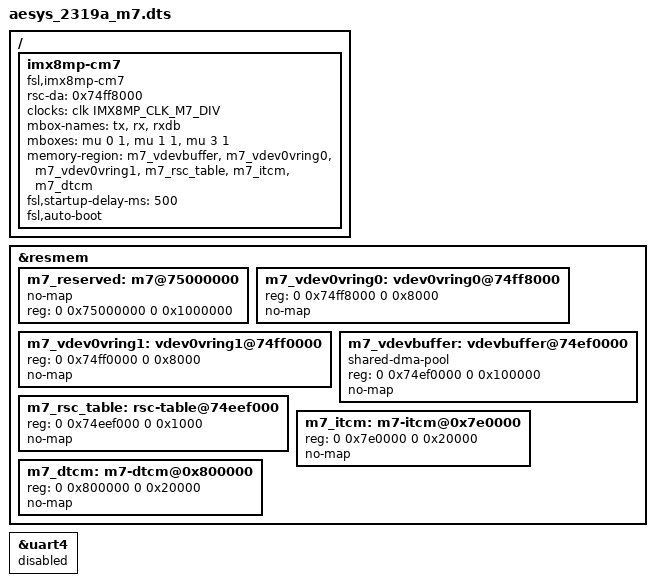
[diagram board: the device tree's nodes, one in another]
// SPDX-License-Identifier: (GPL-2.0 OR MIT)
/*
 * Copyright 2020 NXP
 */

/dts-v1/;

#include "aesys_2319a.dts"

&resmem {
	m7_reserved: m7@75000000 {
		no-map;
		reg = <0 0x75000000 0 0x1000000>;
	};

	m7_vdev0vring0: vdev0vring0@74ff8000 {
		reg = <0 0x74ff8000 0 0x8000>;
		no-map;
	};

	m7_vdev0vring1: vdev0vring1@74ff0000 {
		reg = <0 0x74ff0000 0 0x8000>;
		no-map;
	};

	m7_vdevbuffer: vdevbuffer@74ef0000 {
		compatible = "shared-dma-pool";
		reg = <0 0x74ef0000 0 0x100000>;
		no-map;
	};

	m7_rsc_table: rsc-table@74eef000 {
		reg = <0 0x74eef000 0 0x1000>;
		no-map;
	};

	m7_itcm: m7-itcm@0x7e0000 {
		reg = <0 0x7e0000 0 0x20000>;
		no-map;
	};

	m7_dtcm: m7-dtcm@0x800000 {
		reg = <0 0x800000 0 0x20000>;
		no-map;
	};
};


/ {
	imx8mp-cm7 {
		compatible = "fsl,imx8mp-cm7";
		rsc-da = <0x74ff8000>;
		clocks = <&clk IMX8MP_CLK_M7_DIV>;
		clock-names = "core";
		mbox-names = "tx", "rx", "rxdb";
		mboxes = <&mu 0 1
			  &mu 1 1
			  &mu 3 1>;
		memory-region = <&m7_vdevbuffer>, <&m7_vdev0vring0>, <&m7_vdev0vring1>, <&m7_rsc_table>, <&m7_itcm>, <&m7_dtcm>;
		status = "okay";
		fsl,startup-delay-ms = <500>;
		fsl,auto-boot;
	};
};

/*
 * ATTENTION: M7 may use IPs like below
 * UART4
 */
&uart4 {
	status = "disabled";
};
